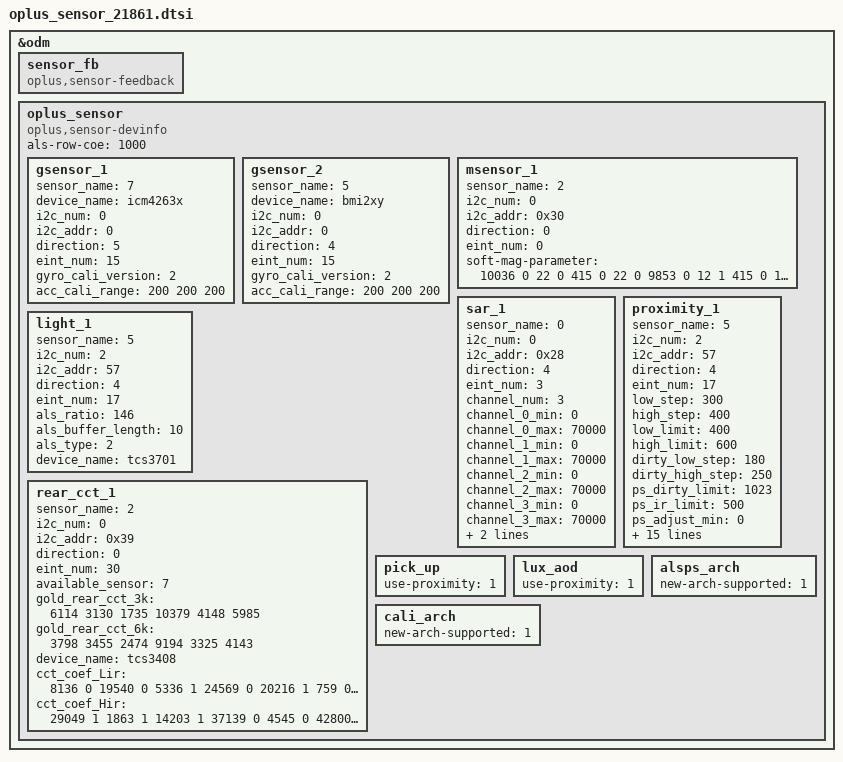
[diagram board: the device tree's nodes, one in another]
&odm {
	sensor_fb: sensor_fb {
		compatible = "oplus,sensor-feedback";
	};
	oplus_sensor:oplus_sensor {
		compatible = "oplus,sensor-devinfo";
		als-row-coe = <1000>;
		/* sensor start */
       		/* 
		enum {
        	        LIS3DH,
			LSM6DS3,
			BMI160,
			LIS2HH12,
			LSM6DSM,
			BMI2XY,
			LSM6DSO,
			BMA4XY,
			SC7A20,
			ICM4X6XX,
		};
		*/
		gsensor_1: gsensor_1 {
			status = "okay";
			sensor_name = <7>;//icm4263x
			device_name = "icm4263x";
			i2c_num = <0>;
			i2c_addr = <0>;
			direction = <5>;
			eint_num = <15>;
			gyro_cali_version= <2>; //should be always v2 for lsm6dso
			acc_cali_range= <200 200 200>;
		};
		gsensor_2: gsensor_2 {
			status = "okay";
			sensor_name = <5>;//icm4263x
			device_name = "bmi2xy";
			i2c_num = <0>;
			i2c_addr = <0>;
			direction = <4>;
			eint_num = <15>;
			gyro_cali_version= <2>; //should be always v2 for lsm6dso
			acc_cali_range= <200 200 200>;
		};
		/*
		enum {
			AKM09911,
			MMC3530,
			MMC5603,
			MXG4300,
		};
		*/
		msensor_1: msensor_1 {
			status = "okay";
			sensor_name = <2>;//MMC5603
			i2c_num = <0>;
			i2c_addr = <0x30>;
			direction = <0>;
			eint_num = <0>;
			soft-mag-parameter = <10036 0 22 0 415 0 22 0 9853 0 12 1 415 0 12 1 10135 0>;
		};
		/*
		enum {
			SX933x
		};
		*/
		sar_1: sar_1 {
			status = "okay";
			sensor_name = <0>;//SX933x
			i2c_num = <0>;
			i2c_addr = <0x28>;
			direction = <4>;
			eint_num = <3>;
			channel_num = <3>;
			channel_0_min = <0>;
			channel_0_max = <70000>;
			channel_1_min = <0>;
			channel_1_max = <70000>;
			channel_2_min = <0>;
			channel_2_max = <70000>;
			channel_3_min = <0>;
			channel_3_max = <70000>;
			reg_table_num = <1>;
			use_far_near = <1>;
		};
		/*
		enum {
			TMD2725,
			APSD9922,
			STK3335,
			STK3331,
			STK2232,
			TCS3701,
			STK32600,
		};
		*/
		proximity_1: proximity_1 {
			status = "okay";
			sensor_name = <5>;//TCS3701
			i2c_num = <2>;
			i2c_addr = <57>;
			direction = <4>;
			eint_num = <17>;
			low_step = <300>;
			high_step = <400>;
			low_limit = <400>;
			high_limit = <600>;
			dirty_low_step = <180>;
			dirty_high_step = <250>;
			ps_dirty_limit = <1023>;
			ps_ir_limit = <500>;
			ps_adjust_min = <0>;
			ps_adjust_max = <600>;
			sampling_count = <5>;
			step_max = <400>;
			step_min = <110>;
			step_div = <1500>;
			anti_shake_delta = <80>;
			dynamic_cali_max = <1024>;
			raw2offset_radio = <31200>;
			offset_max = <250>;
			offset_range_min = <255>;
			offset_range_max = <255>;
			force_cali_limit = <2000>;
			cali_jitter_limit = <30>;
			cal_offset_margin = <200>;
			sensor-reg = <0xBC 0xFB
					0xB9 0x1C>;
		};
		light_1: light_1 {
			status = "okay";
			sensor_name = <5>;//TCS3701
			i2c_num = <2>;
			i2c_addr = <57>;
			direction = <4>;
			eint_num = <17>;
			als_ratio = <146>;
			als_buffer_length = <10>;
			als_type = <2>;
			device_name = "tcs3701";
		};
		/*
		enum {
			STK37600,
			MN29005,
			TCS3408,
		};
		*/
		rear_cct_1: rear_cct_1 {
			status = "okay";
			sensor_name = <2>;//TCS3408
			i2c_num = <0>;
			i2c_addr = <0x39>;
			direction = <0>;
			eint_num = <30>;
			available_sensor = <7>; // bit 0: rear als, bit 1: rear cct, bit 2: rear flicker
			gold_rear_cct_3k = <6114 3130 1735 10379 4148 5985>; // 3000k gold parameter
			gold_rear_cct_6k = <3798 3455 2474 9194 3325 4143>;  // 6000k gold parameter
			device_name = "tcs3408";
			cct_coef_Lir = <8136 0 19540 0 5336 1 24569 0 20216 1 759 0 52216 0 12308 1 14366 0 12190 1 59343 1 101442 1 117326 0 82091 0 61698 1>;
			cct_coef_Hir = <29049 1 1863 1 14203 1 37139 0 4545 0 42800 1 29940 0 30553 1 38668 0 3659 0 83220 1 117390 1 96321 0 65008 0 18250 0>;
		};
		pick_up: pick_up {
			status = "okay";
			use-proximity = <1>;
		};
		lux_aod: lux_aod {
			status = "okay";
			use-proximity = <1>;
		};
		alsps_arch: alsps_arch {
			status = "okay";
			new-arch-supported = <1>;
		};
		cali_arch: cali_arch {
			status = "okay";
			new-arch-supported = <1>;
		};
	};
/* sensor end */
};
